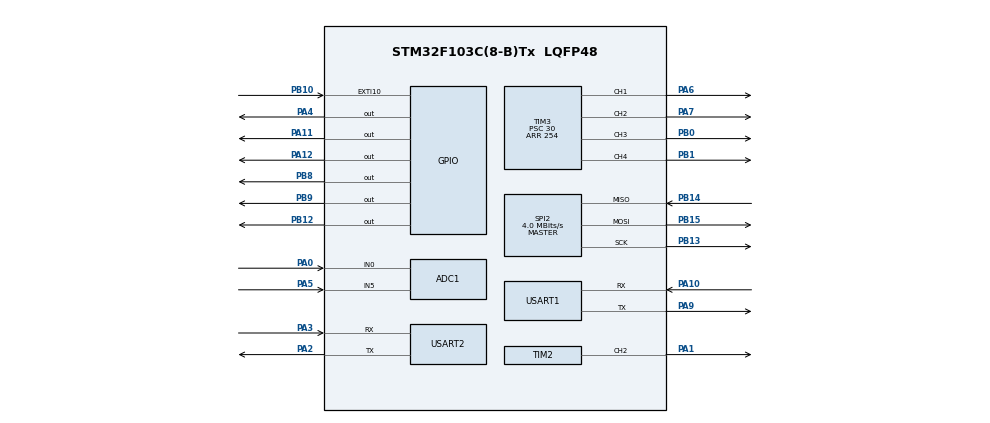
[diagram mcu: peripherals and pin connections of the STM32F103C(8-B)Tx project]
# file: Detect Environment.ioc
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ADC1.Channel-1\#ChannelRegularConversion=ADC_CHANNEL_0
ADC1.Channel-2\#ChannelRegularConversion=ADC_CHANNEL_5
ADC1.ContinuousConvMode=ENABLE
ADC1.NbrOfConversion=2
ADC1.NbrOfConversionFlag=1
ADC1.Rank-1\#ChannelRegularConversion=1
ADC1.Rank-2\#ChannelRegularConversion=2
ADC1.SamplingTime-1\#ChannelRegularConversion=ADC_SAMPLETIME_55CYCLES_5
ADC1.SamplingTime-2\#ChannelRegularConversion=ADC_SAMPLETIME_55CYCLES_5
ADC1.master=1
Dma.ADC1.0.Direction=DMA_PERIPH_TO_MEMORY
Dma.ADC1.0.Instance=DMA1_Channel1
Dma.ADC1.0.MemDataAlignment=DMA_MDATAALIGN_HALFWORD
Dma.ADC1.0.MemInc=DMA_MINC_ENABLE
Dma.ADC1.0.Mode=DMA_CIRCULAR
Dma.ADC1.0.PeriphDataAlignment=DMA_PDATAALIGN_HALFWORD
Dma.ADC1.0.PeriphInc=DMA_PINC_DISABLE
Dma.ADC1.0.Priority=DMA_PRIORITY_MEDIUM
Dma.Request0=ADC1
Dma.Request1=USART2_RX
Dma.USART2_RX.1.Direction=DMA_PERIPH_TO_MEMORY
Dma.USART2_RX.1.Instance=DMA1_Channel6
Dma.USART2_RX.1.MemDataAlignment=DMA_MDATAALIGN_BYTE
Dma.USART2_RX.1.MemInc=DMA_MINC_ENABLE
Dma.USART2_RX.1.Mode=DMA_NORMAL
Dma.USART2_RX.1.PeriphDataAlignment=DMA_PDATAALIGN_BYTE
Dma.USART2_RX.1.PeriphInc=DMA_PINC_DISABLE
Dma.USART2_RX.1.Priority=DMA_PRIORITY_HIGH
FREERTOS.Tasks01=defaultTask,24,128,StartDefaultTask,Default,NULL,Dynamic,NULL,NULL
FREERTOS.configGENERATE_RUN_TIME_STATS=1
FREERTOS.configTOTAL_HEAP_SIZE=8192
FREERTOS.configUSE_IDLE_HOOK=1
FREERTOS.configUSE_STATS_FORMATTING_FUNCTIONS=1
Mcu.Family=STM32F1
Mcu.Name=STM32F103C(8-B)Tx
Mcu.Package=LQFP48
NVIC.EXTI15_10_IRQn=true\:5\:0\:false\:false\:true\:true\:true\:true\:true
NVIC.PriorityGroup=NVIC_PRIORITYGROUP_4
NVIC.TIM4_IRQn=true\:15\:0\:false\:false\:true\:false\:false\:true\:true
NVIC.TimeBase=TIM4_IRQn
NVIC.TimeBaseIP=TIM4
NVIC.USART2_IRQn=true\:5\:0\:false\:false\:true\:true\:true\:true\:true
PA0-WKUP.Signal=ADCx_IN0
PA1.Signal=S_TIM2_CH2
PA10.Mode=Asynchronous
PA10.Signal=USART1_RX
PA11.GPIO_Speed=GPIO_SPEED_FREQ_HIGH
PA11.Signal=GPIO_Output
PA12.GPIO_Speed=GPIO_SPEED_FREQ_HIGH
PA12.Signal=GPIO_Output
PA13.Mode=Serial_Wire
PA13.Signal=SYS_JTMS-SWDIO
PA14.Mode=Serial_Wire
PA14.Signal=SYS_JTCK-SWCLK
PA2.Mode=Asynchronous
PA2.Signal=USART2_TX
PA3.Mode=Asynchronous
PA3.Signal=USART2_RX
PA4.GPIO_ModeDefaultOutputPP=GPIO_MODE_OUTPUT_OD
PA4.GPIO_PuPd=GPIO_NOPULL
PA4.GPIO_Speed=GPIO_SPEED_FREQ_HIGH
PA4.PinState=GPIO_PIN_SET
PA4.Signal=GPIO_Output
PA5.Signal=ADCx_IN5
PA6.Signal=S_TIM3_CH1
PA7.Signal=S_TIM3_CH2
PA9.Mode=Asynchronous
PA9.Signal=USART1_TX
PB0.Signal=S_TIM3_CH3
PB1.Signal=S_TIM3_CH4
PB10.GPIO_ModeDefaultEXTI=GPIO_MODE_IT_FALLING
PB10.GPIO_PuPd=GPIO_PULLUP
PB10.Signal=GPXTI10
PB12.GPIO_Speed=GPIO_SPEED_FREQ_HIGH
PB12.PinState=GPIO_PIN_SET
PB12.Signal=GPIO_Output
PB13.Mode=Full_Duplex_Master
PB13.Signal=SPI2_SCK
PB14.Mode=Full_Duplex_Master
PB14.Signal=SPI2_MISO
PB15.Mode=Full_Duplex_Master
PB15.Signal=SPI2_MOSI
PB8.GPIO_ModeDefaultOutputPP=GPIO_MODE_OUTPUT_OD
PB8.GPIO_PuPd=GPIO_NOPULL
PB8.GPIO_Speed=GPIO_SPEED_FREQ_HIGH
PB8.PinState=GPIO_PIN_SET
PB8.Signal=GPIO_Output
PB9.GPIO_ModeDefaultOutputPP=GPIO_MODE_OUTPUT_OD
PB9.GPIO_PuPd=GPIO_NOPULL
PB9.GPIO_Speed=GPIO_SPEED_FREQ_HIGH
PB9.PinState=GPIO_PIN_SET
PB9.Signal=GPIO_Output
ProjectManager.HeapSize=0x200
ProjectManager.StackSize=0x400
ProjectManager.TargetToolchain=MDK-ARM V5.32
RCC.APB1Freq_Value=8000000
RCC.APB2Freq_Value=8000000
SH.ADCx_IN0.0=ADC1_IN0,IN0
SH.ADCx_IN5.0=ADC1_IN5,IN5
SH.S_TIM2_CH2.0=TIM2_CH2,PWM Generation2 CH2
SH.S_TIM3_CH1.0=TIM3_CH1,PWM Generation1 CH1
SH.S_TIM3_CH2.0=TIM3_CH2,PWM Generation2 CH2
SH.S_TIM3_CH3.0=TIM3_CH3,PWM Generation3 CH3
SH.S_TIM3_CH4.0=TIM3_CH4,PWM Generation4 CH4
SPI2.CalculateBaudRate=4.0 MBits/s
SPI2.Direction=SPI_DIRECTION_2LINES
SPI2.Mode=SPI_MODE_MASTER
SPI2.VirtualType=VM_MASTER
TIM1.AutoReloadPreload=TIM_AUTORELOAD_PRELOAD_ENABLE
TIM1.Prescaler=7
TIM2.AutoReloadPreload=TIM_AUTORELOAD_PRELOAD_ENABLE
TIM2.Channel-PWM\ Generation2\ CH2=TIM_CHANNEL_2
TIM2.OCPolarity_2=TIM_OCPOLARITY_LOW
TIM2.Period=99
TIM2.Prescaler=7
TIM3.AutoReloadPreload=TIM_AUTORELOAD_PRELOAD_ENABLE
TIM3.Channel-PWM\ Generation1\ CH1=TIM_CHANNEL_1
TIM3.Channel-PWM\ Generation2\ CH2=TIM_CHANNEL_2
TIM3.Channel-PWM\ Generation3\ CH3=TIM_CHANNEL_3
TIM3.Channel-PWM\ Generation4\ CH4=TIM_CHANNEL_4
TIM3.OCPolarity_1=TIM_OCPOLARITY_LOW
TIM3.OCPolarity_2=TIM_OCPOLARITY_LOW
TIM3.OCPolarity_3=TIM_OCPOLARITY_LOW
TIM3.Period=254
TIM3.Prescaler=30
USART1.VirtualMode=VM_ASYNC
USART2.VirtualMode=VM_ASYNC
VP_FREERTOS_VS_CMSIS_V2.Mode=CMSIS_V2
VP_SYS_VS_tim4.Mode=TIM4
VP_TIM1_VS_ClockSourceINT.Mode=Internal
VP_TIM2_VS_ClockSourceINT.Mode=Internal
VP_TIM3_VS_ClockSourceINT.Mode=Internal
board=custom

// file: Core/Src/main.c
/* USER CODE BEGIN Header */
/**
  ******************************************************************************
  * @file           : main.c
  * @brief          : Main program body
  ******************************************************************************
  * @attention
  *
  * Copyright (c) 2026 STMicroelectronics.
  * All rights reserved.
  *
  * This software is licensed under terms that can be found in the LICENSE file
  * in the root directory of this software component.
  * If no LICENSE file comes with this software, it is provided AS-IS.
  *
  ******************************************************************************
  */
/* USER CODE END Header */
#include "main.h"
#include "cmsis_os.h"

/* USER CODE BEGIN Includes */
#include "includes.h"
/* USER CODE END Includes */

/* USER CODE BEGIN PD */
#define APP_Start_ADDRESS   0x08008000
/* USER CODE END PD */

ADC_HandleTypeDef hadc1;
DMA_HandleTypeDef hdma_adc1;

SPI_HandleTypeDef hspi2;

TIM_HandleTypeDef htim1;
TIM_HandleTypeDef htim2;
TIM_HandleTypeDef htim3;

UART_HandleTypeDef huart1;
UART_HandleTypeDef huart2;
DMA_HandleTypeDef hdma_usart2_rx;

/* Definitions for defaultTask */
osThreadId_t defaultTaskHandle;
const osThreadAttr_t defaultTask_attributes = {
  .name = "defaultTask",
  .stack_size = 128 * 4,
  .priority = (osPriority_t) osPriorityNormal,
};

void SystemClock_Config(void);
static void MX_GPIO_Init(void);
static void MX_DMA_Init(void);
static void MX_ADC1_Init(void);
static void MX_SPI2_Init(void);
static void MX_TIM1_Init(void);
static void MX_TIM2_Init(void);
static void MX_TIM3_Init(void);
static void MX_USART1_UART_Init(void);
static void MX_USART2_UART_Init(void);
void StartDefaultTask(void *argument);

int main(void)
{
  /* USER CODE BEGIN 1 */
	__disable_irq();//先禁用全局中断
  /* USER CODE END 1 */

  /* MCU Configuration--------------------------------------------------------*/

  /* Reset of all peripherals, Initializes the Flash interface and the Systick. */
  HAL_Init();

  /* Configure the system clock */
  SystemClock_Config();

  /* USER CODE BEGIN SysInit */
 	SCB->VTOR = APP_Start_ADDRESS;//中断向量表重映射
  /* USER CODE END SysInit */

  /* Initialize all configured peripherals */
  MX_GPIO_Init();
  MX_DMA_Init();
  MX_ADC1_Init();
  MX_SPI2_Init();
  MX_TIM1_Init();
  MX_TIM2_Init();
  MX_TIM3_Init();
  MX_USART1_UART_Init();
  MX_USART2_UART_Init();
  /* USER CODE BEGIN 2 */

  EXTI->PR = 0xFFFFFFFF;// 清除所有 EXTI 挂起标志（保险）
  for(int i=0; i<8; i++)
  {
    NVIC->ICPR[i] = 0xFFFFFFFF;// 清除 NVIC 所有挂起中断（彻底解决乱触发）
  }
	__enable_irq();
  /* USER CODE END 2 */

  /* Init scheduler */
  osKernelInitialize();

  /* Create the thread(s) */
  /* creation of defaultTask */
  defaultTaskHandle = osThreadNew(StartDefaultTask, NULL, &defaultTask_attributes);

  /* USER CODE BEGIN RTOS_EVENTS */
  /* add events, ... */
  app_init();
  /* USER CODE END RTOS_EVENTS */

  /* Start scheduler */
  osKernelStart();

  /* We should never get here as control is now taken by the scheduler */
  /* Infinite loop */
  while (1)
  {

  }
}

void SystemClock_Config(void)
{
  RCC_OscInitTypeDef RCC_OscInitStruct = {0};
  RCC_ClkInitTypeDef RCC_ClkInitStruct = {0};
  RCC_PeriphCLKInitTypeDef PeriphClkInit = {0};

  /** Initializes the RCC Oscillators according to the specified parameters
  * in the RCC_OscInitTypeDef structure.
  */
  RCC_OscInitStruct.OscillatorType = RCC_OSCILLATORTYPE_HSI;
  RCC_OscInitStruct.HSIState = RCC_HSI_ON;
  RCC_OscInitStruct.HSICalibrationValue = RCC_HSICALIBRATION_DEFAULT;
  RCC_OscInitStruct.PLL.PLLState = RCC_PLL_NONE;
  if (HAL_RCC_OscConfig(&RCC_OscInitStruct) != HAL_OK)
  {
    Error_Handler();
  }

  /** Initializes the CPU, AHB and APB buses clocks
  */
  RCC_ClkInitStruct.ClockType = RCC_CLOCKTYPE_HCLK|RCC_CLOCKTYPE_SYSCLK
                              |RCC_CLOCKTYPE_PCLK1|RCC_CLOCKTYPE_PCLK2;
  RCC_ClkInitStruct.SYSCLKSource = RCC_SYSCLKSOURCE_HSI;
  RCC_ClkInitStruct.AHBCLKDivider = RCC_SYSCLK_DIV1;
  RCC_ClkInitStruct.APB1CLKDivider = RCC_HCLK_DIV1;
  RCC_ClkInitStruct.APB2CLKDivider = RCC_HCLK_DIV1;

  if (HAL_RCC_ClockConfig(&RCC_ClkInitStruct, FLASH_LATENCY_0) != HAL_OK)
  {
    Error_Handler();
  }
  PeriphClkInit.PeriphClockSelection = RCC_PERIPHCLK_ADC;
  PeriphClkInit.AdcClockSelection = RCC_ADCPCLK2_DIV2;
  if (HAL_RCCEx_PeriphCLKConfig(&PeriphClkInit) != HAL_OK)
  {
    Error_Handler();
  }
}

static void MX_ADC1_Init(void)
{

  ADC_ChannelConfTypeDef sConfig = {0};

  /** Common config
  */
  hadc1.Instance = ADC1;
  hadc1.Init.ScanConvMode = ADC_SCAN_ENABLE;
  hadc1.Init.ContinuousConvMode = ENABLE;
  hadc1.Init.DiscontinuousConvMode = DISABLE;
  hadc1.Init.ExternalTrigConv = ADC_SOFTWARE_START;
  hadc1.Init.DataAlign = ADC_DATAALIGN_RIGHT;
  hadc1.Init.NbrOfConversion = 2;
  if (HAL_ADC_Init(&hadc1) != HAL_OK)
  {
    Error_Handler();
  }

  /** Configure Regular Channel
  */
  sConfig.Channel = ADC_CHANNEL_0;
  sConfig.Rank = ADC_REGULAR_RANK_1;
  sConfig.SamplingTime = ADC_SAMPLETIME_55CYCLES_5;
  if (HAL_ADC_ConfigChannel(&hadc1, &sConfig) != HAL_OK)
  {
    Error_Handler();
  }

  /** Configure Regular Channel
  */
  sConfig.Channel = ADC_CHANNEL_5;
  sConfig.Rank = ADC_REGULAR_RANK_2;
  if (HAL_ADC_ConfigChannel(&hadc1, &sConfig) != HAL_OK)
  {
    Error_Handler();
  }

}

static void MX_SPI2_Init(void)
{

  /* SPI2 parameter configuration*/
  hspi2.Instance = SPI2;
  hspi2.Init.Mode = SPI_MODE_MASTER;
  hspi2.Init.Direction = SPI_DIRECTION_2LINES;
  hspi2.Init.DataSize = SPI_DATASIZE_8BIT;
  hspi2.Init.CLKPolarity = SPI_POLARITY_LOW;
  hspi2.Init.CLKPhase = SPI_PHASE_1EDGE;
  hspi2.Init.NSS = SPI_NSS_SOFT;
  hspi2.Init.BaudRatePrescaler = SPI_BAUDRATEPRESCALER_2;
  hspi2.Init.FirstBit = SPI_FIRSTBIT_MSB;
  hspi2.Init.TIMode = SPI_TIMODE_DISABLE;
  hspi2.Init.CRCCalculation = SPI_CRCCALCULATION_DISABLE;
  hspi2.Init.CRCPolynomial = 10;
  if (HAL_SPI_Init(&hspi2) != HAL_OK)
  {
    Error_Handler();
  }

}

static void MX_TIM1_Init(void)
{

  TIM_ClockConfigTypeDef sClockSourceConfig = {0};
  TIM_MasterConfigTypeDef sMasterConfig = {0};

  htim1.Instance = TIM1;
  htim1.Init.Prescaler = 7;
  htim1.Init.CounterMode = TIM_COUNTERMODE_UP;
  htim1.Init.Period = 65535;
  htim1.Init.ClockDivision = TIM_CLOCKDIVISION_DIV1;
  htim1.Init.RepetitionCounter = 0;
  htim1.Init.AutoReloadPreload = TIM_AUTORELOAD_PRELOAD_ENABLE;
  if (HAL_TIM_Base_Init(&htim1) != HAL_OK)
  {
    Error_Handler();
  }
  sClockSourceConfig.ClockSource = TIM_CLOCKSOURCE_INTERNAL;
  if (HAL_TIM_ConfigClockSource(&htim1, &sClockSourceConfig) != HAL_OK)
  {
    Error_Handler();
  }
  sMasterConfig.MasterOutputTrigger = TIM_TRGO_RESET;
  sMasterConfig.MasterSlaveMode = TIM_MASTERSLAVEMODE_DISABLE;
  if (HAL_TIMEx_MasterConfigSynchronization(&htim1, &sMasterConfig) != HAL_OK)
  {
    Error_Handler();
  }

}

static void MX_TIM2_Init(void)
{

  TIM_ClockConfigTypeDef sClockSourceConfig = {0};
  TIM_MasterConfigTypeDef sMasterConfig = {0};
  TIM_OC_InitTypeDef sConfigOC = {0};

  htim2.Instance = TIM2;
  htim2.Init.Prescaler = 7;
  htim2.Init.CounterMode = TIM_COUNTERMODE_UP;
  htim2.Init.Period = 99;
  htim2.Init.ClockDivision = TIM_CLOCKDIVISION_DIV1;
  htim2.Init.AutoReloadPreload = TIM_AUTORELOAD_PRELOAD_ENABLE;
  if (HAL_TIM_Base_Init(&htim2) != HAL_OK)
  {
    Error_Handler();
  }
  sClockSourceConfig.ClockSource = TIM_CLOCKSOURCE_INTERNAL;
  if (HAL_TIM_ConfigClockSource(&htim2, &sClockSourceConfig) != HAL_OK)
  {
    Error_Handler();
  }
  if (HAL_TIM_PWM_Init(&htim2) != HAL_OK)
  {
    Error_Handler();
  }
  sMasterConfig.MasterOutputTrigger = TIM_TRGO_RESET;
  sMasterConfig.MasterSlaveMode = TIM_MASTERSLAVEMODE_DISABLE;
  if (HAL_TIMEx_MasterConfigSynchronization(&htim2, &sMasterConfig) != HAL_OK)
  {
    Error_Handler();
  }
  sConfigOC.OCMode = TIM_OCMODE_PWM1;
  sConfigOC.Pulse = 0;
  sConfigOC.OCPolarity = TIM_OCPOLARITY_LOW;
  sConfigOC.OCFastMode = TIM_OCFAST_DISABLE;
  if (HAL_TIM_PWM_ConfigChannel(&htim2, &sConfigOC, TIM_CHANNEL_2) != HAL_OK)
  {
    Error_Handler();
  }
  HAL_TIM_MspPostInit(&htim2);

}

static void MX_TIM3_Init(void)
{

  TIM_ClockConfigTypeDef sClockSourceConfig = {0};
  TIM_MasterConfigTypeDef sMasterConfig = {0};
  TIM_OC_InitTypeDef sConfigOC = {0};

  htim3.Instance = TIM3;
  htim3.Init.Prescaler = 30;
  htim3.Init.CounterMode = TIM_COUNTERMODE_UP;
  htim3.Init.Period = 254;
  htim3.Init.ClockDivision = TIM_CLOCKDIVISION_DIV1;
  htim3.Init.AutoReloadPreload = TIM_AUTORELOAD_PRELOAD_ENABLE;
  if (HAL_TIM_Base_Init(&htim3) != HAL_OK)
  {
    Error_Handler();
  }
  sClockSourceConfig.ClockSource = TIM_CLOCKSOURCE_INTERNAL;
  if (HAL_TIM_ConfigClockSource(&htim3, &sClockSourceConfig) != HAL_OK)
  {
    Error_Handler();
  }
  if (HAL_TIM_PWM_Init(&htim3) != HAL_OK)
  {
    Error_Handler();
  }
  sMasterConfig.MasterOutputTrigger = TIM_TRGO_RESET;
  sMasterConfig.MasterSlaveMode = TIM_MASTERSLAVEMODE_DISABLE;
  if (HAL_TIMEx_MasterConfigSynchronization(&htim3, &sMasterConfig) != HAL_OK)
  {
    Error_Handler();
  }
  sConfigOC.OCMode = TIM_OCMODE_PWM1;
  sConfigOC.Pulse = 0;
  sConfigOC.OCPolarity = TIM_OCPOLARITY_LOW;
  sConfigOC.OCFastMode = TIM_OCFAST_DISABLE;
  if (HAL_TIM_PWM_ConfigChannel(&htim3, &sConfigOC, TIM_CHANNEL_1) != HAL_OK)
  {
    Error_Handler();
  }
  if (HAL_TIM_PWM_ConfigChannel(&htim3, &sConfigOC, TIM_CHANNEL_2) != HAL_OK)
  {
    Error_Handler();
  }
  if (HAL_TIM_PWM_ConfigChannel(&htim3, &sConfigOC, TIM_CHANNEL_3) != HAL_OK)
  {
    Error_Handler();
  }
  sConfigOC.OCPolarity = TIM_OCPOLARITY_HIGH;
  if (HAL_TIM_PWM_ConfigChannel(&htim3, &sConfigOC, TIM_CHANNEL_4) != HAL_OK)
  {
    Error_Handler();
  }
  HAL_TIM_MspPostInit(&htim3);

}

static void MX_USART1_UART_Init(void)
{

  huart1.Instance = USART1;
  huart1.Init.BaudRate = 115200;
  huart1.Init.WordLength = UART_WORDLENGTH_8B;
  huart1.Init.StopBits = UART_STOPBITS_1;
  huart1.Init.Parity = UART_PARITY_NONE;
  huart1.Init.Mode = UART_MODE_TX_RX;
  huart1.Init.HwFlowCtl = UART_HWCONTROL_NONE;
  huart1.Init.OverSampling = UART_OVERSAMPLING_16;
  if (HAL_UART_Init(&huart1) != HAL_OK)
  {
    Error_Handler();
  }

}

static void MX_USART2_UART_Init(void)
{

  huart2.Instance = USART2;
  huart2.Init.BaudRate = 115200;
  huart2.Init.WordLength = UART_WORDLENGTH_8B;
  huart2.Init.StopBits = UART_STOPBITS_1;
  huart2.Init.Parity = UART_PARITY_NONE;
  huart2.Init.Mode = UART_MODE_TX_RX;
  huart2.Init.HwFlowCtl = UART_HWCONTROL_NONE;
  huart2.Init.OverSampling = UART_OVERSAMPLING_16;
  if (HAL_UART_Init(&huart2) != HAL_OK)
  {
    Error_Handler();
  }

}

static void MX_DMA_Init(void)
{

  /* DMA controller clock enable */
  __HAL_RCC_DMA1_CLK_ENABLE();

}

static void MX_GPIO_Init(void)
{
  GPIO_InitTypeDef GPIO_InitStruct = {0};

  /* GPIO Ports Clock Enable */
  __HAL_RCC_GPIOA_CLK_ENABLE();
  __HAL_RCC_GPIOB_CLK_ENABLE();

  /*Configure GPIO pin Output Level */
  HAL_GPIO_WritePin(GPIOA, GPIO_PIN_4, GPIO_PIN_SET);

  /*Configure GPIO pin Output Level */
  HAL_GPIO_WritePin(GPIOB, GPIO_PIN_12|GPIO_PIN_8|GPIO_PIN_9, GPIO_PIN_SET);

  /*Configure GPIO pin Output Level */
  HAL_GPIO_WritePin(GPIOA, GPIO_PIN_11|GPIO_PIN_12, GPIO_PIN_RESET);

  /*Configure GPIO pin : PA4 */
  GPIO_InitStruct.Pin = GPIO_PIN_4;
  GPIO_InitStruct.Mode = GPIO_MODE_OUTPUT_OD;
  GPIO_InitStruct.Pull = GPIO_NOPULL;
  GPIO_InitStruct.Speed = GPIO_SPEED_FREQ_HIGH;
  HAL_GPIO_Init(GPIOA, &GPIO_InitStruct);

  /*Configure GPIO pin : PB10 */
  GPIO_InitStruct.Pin = GPIO_PIN_10;
  GPIO_InitStruct.Mode = GPIO_MODE_IT_FALLING;
  GPIO_InitStruct.Pull = GPIO_PULLUP;
  HAL_GPIO_Init(GPIOB, &GPIO_InitStruct);

  /*Configure GPIO pin : PB12 */
  GPIO_InitStruct.Pin = GPIO_PIN_12;
  GPIO_InitStruct.Mode = GPIO_MODE_OUTPUT_PP;
  GPIO_InitStruct.Pull = GPIO_NOPULL;
  GPIO_InitStruct.Speed = GPIO_SPEED_FREQ_HIGH;
  HAL_GPIO_Init(GPIOB, &GPIO_InitStruct);

  /*Configure GPIO pins : PA11 PA12 */
  GPIO_InitStruct.Pin = GPIO_PIN_11|GPIO_PIN_12;
  GPIO_InitStruct.Mode = GPIO_MODE_OUTPUT_PP;
  GPIO_InitStruct.Pull = GPIO_NOPULL;
  GPIO_InitStruct.Speed = GPIO_SPEED_FREQ_HIGH;
  HAL_GPIO_Init(GPIOA, &GPIO_InitStruct);

  /*Configure GPIO pins : PB8 PB9 */
  GPIO_InitStruct.Pin = GPIO_PIN_8|GPIO_PIN_9;
  GPIO_InitStruct.Mode = GPIO_MODE_OUTPUT_OD;
  GPIO_InitStruct.Pull = GPIO_NOPULL;
  GPIO_InitStruct.Speed = GPIO_SPEED_FREQ_HIGH;
  HAL_GPIO_Init(GPIOB, &GPIO_InitStruct);

  /* EXTI interrupt init*/
  HAL_NVIC_SetPriority(EXTI15_10_IRQn, 5, 0);
  HAL_NVIC_EnableIRQ(EXTI15_10_IRQn);

}

/* USER CODE BEGIN 4 */
int fputc(int ch, FILE *f)
{
	HAL_UART_Transmit(&huart1, (const uint8_t *)&ch, 1, HAL_MAX_DELAY);
	return ch;
}
/* USER CODE END 4 */

void StartDefaultTask(void *argument)
{
  for(;;)
  {
    osDelay(1);
  }
}

void HAL_TIM_PeriodElapsedCallback(TIM_HandleTypeDef *htim)
{
  if (htim->Instance == TIM4) {
    HAL_IncTick();
  }
}

void Error_Handler(void)
{
  __disable_irq();
  while (1)
  {
  }
}

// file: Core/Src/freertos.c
/* USER CODE BEGIN Header */
/**
  ******************************************************************************
  * File Name          : freertos.c
  * Description        : Code for freertos applications
  ******************************************************************************
  * @attention
  *
  * Copyright (c) 2026 STMicroelectronics.
  * All rights reserved.
  *
  * This software is licensed under terms that can be found in the LICENSE file
  * in the root directory of this software component.
  * If no LICENSE file comes with this software, it is provided AS-IS.
  *
  ******************************************************************************
  */
/* USER CODE END Header */

#include "FreeRTOS.h"
#include "task.h"
#include "main.h"

/* USER CODE BEGIN Includes */
#include <stdio.h>
/* USER CODE END Includes */

/* USER CODE BEGIN Variables */
char text[512];
/* USER CODE END Variables */

/* Hook prototypes */
void configureTimerForRunTimeStats(void);
unsigned long getRunTimeCounterValue(void);
void vApplicationIdleHook(void);

/* USER CODE BEGIN 1 */
/* Functions needed when configGENERATE_RUN_TIME_STATS is on */
__weak void configureTimerForRunTimeStats(void)
{

}

__weak unsigned long getRunTimeCounterValue(void)
{
  return 0;
  // return system_get_ns()/1000;
}
/* USER CODE END 1 */

/* USER CODE BEGIN 2 */
void vApplicationIdleHook( void )
{
   /* vApplicationIdleHook() will only be called if configUSE_IDLE_HOOK is set
   to 1 in FreeRTOSConfig.h. It will be called on each iteration of the idle
   task. It is essential that code added to this hook function never attempts
   to block in any way (for example, call xQueueReceive() with a block time
   specified, or call vTaskDelay()). If the application makes use of the
   vTaskDelete() API function (as this demo application does) then it is also
   important that vApplicationIdleHook() is permitted to return to its calling
   function, because it is the responsibility of the idle task to clean up
   memory allocated by the kernel to any task that has since been deleted. */
	// int i;
	// // vTaskList(text);//查看堆栈使用情况
	// vTaskGetRunTimeStats(text);//查看CPU使用�?
	// for(i=0;i<16;i++)
  // {
  //   printf("_");
  // }
	// printf("\r\n");
	// printf("%s",text);
	// printf("\r\n");
}
/* USER CODE END 2 */
